AUTOSAR XML (schema 00044)
package /ComponentTypes
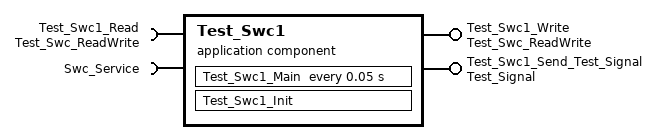
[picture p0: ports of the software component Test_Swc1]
  application sw component type Test_Swc1
    provide port Test_Swc1_Write: nonqueued-sender-com-spec=u8_Signal, provided-interface=Test_Swc_ReadWrite
    require port Test_Swc1_Read: nonqueued-receiver-com-spec=data-element=u8_Signal, required-interface=Test_Swc_ReadWrite
    provide port Test_Swc1_Send_Test_Signal: nonqueued-sender-com-spec{data-element=u16_Siganl, init-value=0}, provided-interface=Test_Signal
    require port Swc_Service: client-com-spec=Operation, required-interface=Swc_Service
    behavior Test_Swc1_InternalBehavior
      init event Test_Swc1_InitEvent: start-on-event=Test_Swc1_Init
      timing event TMT_Test_Swc1_Main: start-on-event=Test_Swc1_Main, period=0.05
      runnable Test_Swc1_Main: minimum-start-interval=0.05
        data-receive-point-by-arguments:
          access REC_Test_Swc1_Read_u8_Signal: accessed-variable=Test_Swc1_Read.u8_Signal
        data-send-points:
          access SEND_Test_Swc1_Write_u8_Signal: accessed-variable=Test_Swc1_Write.u8_Signal
          access SEND_Test_Swc1_Send_Test_Signal_u16_Siganl: accessed-variable=Test_Swc1_Send_Test_Signal.u16_Siganl
        sync call SC_Swc_Service_Operation: operation=Swc_Service.Operation
      runnable Test_Swc1_Init
  swc implementation Test_Swc1_Implementation: behavior=Test_Swc1_InternalBehavior
